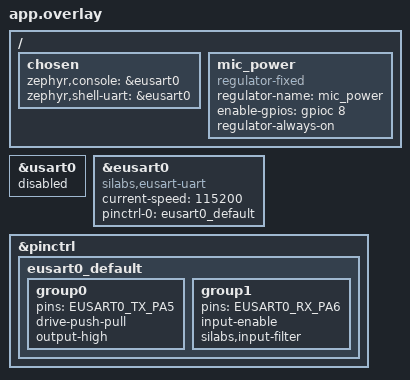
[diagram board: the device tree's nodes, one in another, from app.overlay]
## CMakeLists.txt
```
cmake_minimum_required(VERSION 3.20.0)
find_package(Zephyr REQUIRED HINTS $ENV{ZEPHYR_BASE})
project(silabs_ble_audio_peripheral)

# Module source files for audio, preprocessing, TFLM inference, and BLE
target_sources(app PRIVATE 
    src/main.cpp 
    src/audio.c 
    src/audio_preprocessing.c
    src/inference.cpp
    src/cmsis_nn_cnn_engine.cpp
    src/tcn_inference_engine.cpp
    src/ble_server.c
)

# EMLIB hardware USART and LDMA drivers
target_sources(app PRIVATE /home/acar/zephyrproject/modules/hal/silabs/gecko/emlib/src/em_usart.c)
target_sources(app PRIVATE /home/acar/zephyrproject/modules/hal/silabs/gecko/emlib/src/em_ldma.c)
```

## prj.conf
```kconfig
# =============================================================
# PROJE: Silabs BLE Audio Peripheral
# STRATEJI: USART0 tamamen Zephyr'den alinip EMLIB/I2S'e birakildi.
#           Konsol cikisi EUSART0 uzerinden PA5/PA6'ya (VCOM) yonlendirildi.
# =============================================================

# --- KONSOL: EUSART0 uzerinden UART (PA5/PA6 = VCOM) ---
CONFIG_CONSOLE=y
CONFIG_SERIAL=y
CONFIG_UART_CONSOLE=y
CONFIG_STDOUT_CONSOLE=y
CONFIG_UART_SILABS_EUSART=y

# Zephyr'in USART (eski tip) surecusunu TAMAMEN kapat
# USART0 artik sadece EMLIB tarafindan I2S icin kullanilacak
CONFIG_UART_GECKO=n

# RTT'yi de yedek olarak tut (J-Link bagliyken ise yarar)
CONFIG_USE_SEGGER_RTT=y

# --- BLUETOOTH SERVER AYARLARI (DISABLED FOR MAXIMUM 175KB TFLM ARENA) ---
CONFIG_BT=n

# --- DONANIM KONTROLU ---
CONFIG_PM=n
CONFIG_PINCTRL=y
CONFIG_GPIO=y
CONFIG_DYNAMIC_INTERRUPTS=y
CONFIG_REGULATOR=y
CONFIG_REGULATOR_FIXED=y

# Zephyr I2S/Audio/DMA suruculerini KAPATIYORUZ
# (USART0-I2S icin EMLIB + LDMA dogrudan kullaniyor)
CONFIG_I2S=n
CONFIG_AUDIO=n
CONFIG_DMA=n
CONFIG_SPI=n

# --- KORUMA VE YIGIN (OPTIMIZED STACK/HEAP) ---
CONFIG_ARM_MPU=y
CONFIG_HW_STACK_PROTECTION=y
CONFIG_MAIN_STACK_SIZE=8192
CONFIG_HEAP_MEM_POOL_SIZE=2048
CONFIG_SPEED_OPTIMIZATIONS=y

# --- GUCLENDIRILMIS GUC YONETIMI ---
CONFIG_SOC_GECKO_EMU_DCDC=y
CONFIG_SOC_GECKO_EMU_DCDC_MODE_ON=y

# --- TENSORFLOW LITE MICRO & C++ / DSP CONFIGURATION ---
CONFIG_CPP=y
CONFIG_STD_CPP17=y
CONFIG_REQUIRES_FULL_LIBCPP=y
CONFIG_CBPRINTF_FP_SUPPORT=y

# TensorFlow Lite Micro
CONFIG_TENSORFLOW_LITE_MICRO=y
CONFIG_TENSORFLOW_LITE_MICRO_CMSIS_NN_KERNELS=y
CONFIG_CMSIS_NN=y

# CMSIS-DSP Acceleration & RFFT Transformations
CONFIG_CMSIS_DSP=y
CONFIG_DSP_BACKEND_CMSIS=y
CONFIG_CMSIS_DSP_TRANSFORM=y

# Hardware Floating Point Unit (ARM Cortex-M33 FPU)
CONFIG_FPU=y
```

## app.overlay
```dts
/*
 * STRATEJI:
 * - USART0: Zephyr surucusu DEVRE DISI. EMLIB tarafindan I2S (mikrofon) icin kullanilir.
 * - EUSART0: Zephyr UART konsol surucusu AKTIF. PA5(TX)/PA6(RX) = VCOM pinleri.
 * - Mikrofon I2S pinleri (PD3/PD4/PD5) audio.c icerisinde EMLIB ile dogrudan yapilandirilir.
 */

#include <dt-bindings/pinctrl/silabs/xg24-pinctrl.h>
#include <zephyr/dt-bindings/gpio/gpio.h>
#include <silabs/xg24/clock-hfrcodpll.dtsi>

/ {
    chosen {
        /* Konsol artik EUSART0 uzerinden */
        zephyr,console = &eusart0;
        zephyr,shell-uart = &eusart0;
    };

    /* DATASHEET ONAYLI DONANIMSAL ANAHTAR (PC08/PC09) */
    mic_power: mic_power {
        compatible = "regulator-fixed";
        regulator-name = "mic_power";
        
        /* PC08 High yapilarak multiplexer aciliyor ve mikrofonlar islemciye baglaniyor */
        enable-gpios = <&gpioc 8 GPIO_ACTIVE_HIGH>;
        regulator-always-on; 
    };
};

/* USART0: Zephyr surucusunu TAMAMEN kapat. 
 * EMLIB/audio.c bunu I2S olarak dogrudan yapilandiracak. */
&usart0 {
    status = "disabled";
};

/* EUSART0: UART Konsol Surucusu (PA5=TX, PA6=RX -> VCOM) */
&eusart0 {
    compatible = "silabs,eusart-uart";
    current-speed = <115200>;
    pinctrl-0 = <&eusart0_default>;
    pinctrl-names = "default";
    status = "okay";
};

/* Pin Yapilandirmasi */
&pinctrl {
    /* EUSART0 Konsol Pinleri (VCOM'a baglanir) */
    eusart0_default: eusart0_default {
        group0 {
            pins = <EUSART0_TX_PA5>;
            drive-push-pull;
            output-high;
        };
        group1 {
            pins = <EUSART0_RX_PA6>;
            input-enable;
            silabs,input-filter;
        };
    };
};
```

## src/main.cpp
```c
#include <zephyr/kernel.h>
#include <zephyr/sys/printk.h>
#include <stdio.h>
#include <math.h>
#include "em_cmu.h"
#include "em_device.h"
#include "SEGGER_RTT.h"
#include "config.h"
#include "audio.h"
#include "audio_preprocessing.h"
#include "inference.h"
#include "ble_server.h"
#if (FIRMWARE_OPERATION_MODE == MODE_INJECT_GOLDEN_SAMPLE)
#include "golden_keyboard_typing_pcm.h"
#endif

int main(void) {
    /* 0. BOOST CPU CLOCK TO 80 MHz MAXIMUM PERFORMANCE */
    CMU_HFRCODPLLBandSet(cmuHFRCODPLLFreq_80M0Hz);
    CMU_ClockSelectSet(cmuClock_SYSCLK, cmuSelect_HFRCODPLL);
    SystemCoreClockUpdate();

    /* EARLY HEARTBEAT PRINTK (Guaranteed direct UART output to /dev/ttyACM0) */
    printk("\n\n");
    printk("************************************************************\n");
    printk(" *** EFR32MG24 BOOT TEST: UART CONSOLE LOGGING IS ALIVE! ***\n");
    printk("************************************************************\n\n");

    SEGGER_RTT_Init();
    
    uint32_t cpu_freq_hz = CMU_ClockFreqGet(cmuClock_SYSCLK);
    printf("\n============================================================\n");
    printf(" EFR32MG24 TINYML ESC-50 SOUND CLASSIFICATION PIPELINE\n");
    printf(" Target: Silicon Labs EFR32MG24 DevKit (ARM Cortex-M33)\n");
    printf(" Clock : %lu MHz High-Performance Core Clock\n", cpu_freq_hz / 1000000);
    printf(" Engine: Zephyr RTOS + TensorFlow Lite Micro (CMSIS-NN)\n");
    printf(" Mode  : %s\n", ENABLE_STREAMING_INFERENCE ? 
           "CONTINUOUS SLIDING-WINDOW STREAMING" : "ONE-SHOT CAPTURE");
    printf("============================================================\n\n");

    /* 1. Hardware & Module Initialization */
    printk("-> Step 1: Initializing hardware & TinyML modules...\n");
    audio_init();
    audio_preprocessing_init();
    
    if (inference_init() != 0) {
        printk("[FATAL] TinyML inference initialization failed!\n");
        return -1;
    }

#if ENABLE_BLE_COMMUNICATION
    ble_server_init();

    /* 2. Wait for BLE Client Connection */
    printk("\n-> Step 2: Waiting for BLE Client Connection...\n");
    while (!ble_is_connected_and_ready()) {
        printk(".");
        k_sleep(K_MSEC(500));
    }
    printk("\n-> BLE Connected!\n");
#else
    printk("\n-> [STANDALONE MODE] BLE is disabled. Starting real-time audio inference directly via UART!\n");
#endif

    void *input_tensor_ptr = inference_get_input_tensor_ptr();
    bool is_input_int8 = inference_is_input_int8();
    float scale = 1.0f;
    int32_t zero_point = 0;
    inference_get_input_quant_params(&scale, &zero_point);

#if (FIRMWARE_OPERATION_MODE == MODE_INJECT_GOLDEN_SAMPLE)
    /* ========================================================================
     * 🧪 MODE 2: DIRECT AUDIO INJECTION (GOLDEN ARRAY BENCHMARK - NO MIC)
     * ======================================================================== */
    printk("\n============================================================\n");
    printk(" 🧪 FIRMWARE MODE 2: DIRECT AUDIO INJECTION BENCHMARK\n");
    printk(" Target: Silicon Labs EFR32MG24 DevKit (ARM Cortex-M33)\n");
    printk(" Input : Golden Validation 'keyboard_typing' ESC-50 Array (5-216131-A-32.wav)\n");
    printk(" Bypassing Physical Microphone to Test DSP & Neural Network!\n");
    printk("============================================================\n\n");

    printk("-> Step 1: Running Bit-Exact On-Chip DSP Mel-Spectrogram Extraction...\n");
    audio_preprocess_run_direct(GOLDEN_KEYBOARD_TYPING_PCM, GOLDEN_AUDIO_SAMPLE_COUNT, scale, zero_point, is_input_int8, input_tensor_ptr);

    printk("-> Step 2: Executing 2-Stage Hybrid TinyML Model Inference...\n");
    int predicted_class_id = -1;
    float confidence = 0.0f;

    if (inference_run_direct(&predicted_class_id, &confidence) == 0) {
        const char *class_name = inference_get_class_name(predicted_class_id);
        printk("\n============================================================\n");
        printk(" 🏆 GOLDEN AUDIO INJECTION INFERENCE RESULT:\n");
        printk("   • Injected Sound       : 'keyboard_typing' (5-216131-A-32.wav - Official Unseen Fold-5)\n");
        printk("   • Predicted Class ID   : %d\n", predicted_class_id);
        printk("   • Predicted Sound Name : '%s'\n", class_name);
        printk("   • Prediction Confidence: %d%%\n", (int)(confidence * 100.0f));
        printk("============================================================\n\n");
    } else {
        printk("[ERROR] Inference execution failed!\n");
    }

    while (1) {
        k_sleep(K_SECONDS(2));
    }

#elif (FIRMWARE_OPERATION_MODE == MODE_AUDIO_DUMP_TO_PC)
    /* ========================================================================
     * 🎙️ DIAGNOSTIC MODE: STREAM 3-SECOND MICROPHONE AUDIO TO PC (WAV DUMP)
     * ======================================================================== */
    printk("\n============================================================\n");
    printk(" 🎙️ FIRMWARE MODE: 3-SECOND MICROPHONE AUDIO DUMP TO PC\n");
    printk(" Target: Silicon Labs EFR32MG24 DevKit\n");
    printk(" Rate  : 16000 Hz, 16-bit PCM Mono, Total: 48000 samples (3 sec)\n");
    printk(" Speak, type, or play sounds near the board now!\n");
    printk("============================================================\n\n");

    int dump_iteration = 0;
    while (1) {
        printk("\n-> [READY #%d] 🎙️ Recording 3 seconds of live audio from mic...\n", ++dump_iteration);
        printk("=== AUDIO_DUMP_START ===\n");

        for (int sec = 0; sec < DUMP_RECORD_SECONDS; sec++) {
            audio_record_to_ram();
            int16_t *raw_pcm = get_audio_buffer();

            for (int i = 0; i < AUDIO_RING_BUFFER_SAMPLES; i++) {
                printk("%d\n", (int)raw_pcm[i]);
            }
        }

        printk("=== AUDIO_DUMP_END ===\n");
        printk("-> [OK] 3-second capture complete! Waiting 3 seconds before next clip...\n");
        k_sleep(K_SECONDS(3));
    }

#elif (FIRMWARE_OPERATION_MODE == MODE_REALTIME_INFERENCE)
    /* ========================================================================
     * 🧠 MODE 0: CONTINUOUS SLIDING-WINDOW STREAMING INFERENCE
     * ======================================================================== */
    printk("\n-> [CONTINUOUS STREAMING MODE] Starting Real-Time Acoustic Inference Loop...\n");
    
    /* Zero-initialize the TFLM input tensor buffer to true silence (-128) */
    if (is_input_int8) {
        memset(input_tensor_ptr, -128, SPECTROGRAM_TOTAL_ELEMENTS);
    } else {
        memset(input_tensor_ptr, 0, sizeof(float) * SPECTROGRAM_TOTAL_ELEMENTS);
    }

    /* Squelch threshold defined in config.h (SILENCE_AC_RMS_THRESHOLD) */
    const float SOUND_CONFIDENCE_THRESHOLD = 0.20f; /* 20% minimum confidence (10x random chance in 50 classes) */
    int inference_counter = 0;

    while (1) {
        /* 1. Record 1.0-second audio chunk directly into audio_ring_buffer */
        audio_record_to_ram();
        int16_t *raw_pcm = get_audio_buffer();

        /* 2. Calculate DC Mean & True AC RMS */
        int64_t sum_samples = 0;
        for (int i = 0; i < AUDIO_RING_BUFFER_SAMPLES; i++) {
            sum_samples += raw_pcm[i];
        }
        int16_t dc_mean = (int16_t)(sum_samples / AUDIO_RING_BUFFER_SAMPLES);

        int64_t sum_ac_sq = 0;
        for (int i = 0; i < AUDIO_RING_BUFFER_SAMPLES; i++) {
            int16_t ac_s = raw_pcm[i] - dc_mean;
            sum_ac_sq += ((int32_t)ac_s * ac_s);
        }
        int ac_rms = (int)sqrtf((float)(sum_ac_sq / AUDIO_RING_BUFFER_SAMPLES));

        /* 3. Compute and tile active Mel chunk across full 5.0s (313 frames) to eliminate temporal dilution */
        uint32_t t_dsp_start = k_cycle_get_32();
        audio_preprocess_tile_chunk_direct(raw_pcm, AUDIO_RING_BUFFER_SAMPLES, scale, zero_point, is_input_int8, input_tensor_ptr);
        uint32_t t_dsp_end = k_cycle_get_32();
        uint32_t dsp_time_us = k_cyc_to_us_near32(t_dsp_end - t_dsp_start);

        /* 4. Evaluate Dual-Stage Silence & Confidence Thresholds */
        uint32_t uptime_ms = k_uptime_get_32();
        if (ac_rms < SILENCE_AC_RMS_THRESHOLD) {
            printk("[%02d:%02d.%03d] [#%04d] 🎙️ [AC-RMS: %4d | DSP: %.2f ms] -> [Quiet / Ambient Silence]\n", 
                   (uptime_ms / 60000) % 60, (uptime_ms / 1000) % 60, uptime_ms % 1000,
                   ++inference_counter, ac_rms, (float)dsp_time_us / 1000.0f);
        } else {
            /* Run Hybrid 2-Stage Model Inference */
            int predicted_class_id = -1;
            float confidence = 0.0f;

            if (inference_run_direct(&predicted_class_id, &confidence) == 0) {
                if (confidence >= SOUND_CONFIDENCE_THRESHOLD) {
                    const char *class_name = inference_get_class_name(predicted_class_id);
                    printk("[%02d:%02d.%03d] [#%04d] 🎙️ [AC-RMS: %5d | DSP: %.2f ms] -> 🎯 CONFIDENT SOUND: %-20s (Conf: %2d%%) 🌟\n",
                           (uptime_ms / 60000) % 60, (uptime_ms / 1000) % 60, uptime_ms % 1000,
                           ++inference_counter, ac_rms, (float)dsp_time_us / 1000.0f, class_name, (int)(confidence * 100.0f));
                }
            }
        }
    }
#endif

    return 0;
}
```

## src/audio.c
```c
#include "audio.h"
#include "em_ldma.h"
#include "em_device.h"
#include "em_cmu.h"
#include "em_usart.h"
#include "em_gpio.h" 
#include <zephyr/kernel.h>
#include <zephyr/irq.h>
#include <stdio.h>
#include <stdlib.h>
#include <string.h>

#define DMA_BUF_WORDS 1024

/* ============================================================================
 * AUDIO RING BUFFER CONFIGURATION
 * To eliminate linker RAM overflow and save >125 KB of microcontroller SRAM,
 * we maintain a 1-second streaming ring buffer (16,000 samples = 32 KB RAM)
 * instead of a monolithic 5-second 160 KB array.
 * ============================================================================ */
#ifndef AUDIO_RING_BUFFER_SAMPLES
#define AUDIO_RING_BUFFER_SAMPLES (SAMPLE_RATE * 1) /* 16,000 samples = 32 KB RAM */
#endif

static int16_t audio_ring_buffer[AUDIO_RING_BUFFER_SAMPLES];
static uint16_t dma_buf[DMA_BUF_WORDS] __attribute__((aligned(4)));
static LDMA_Descriptor_t dma_desc;

static void check_usart_errors(const char* stage) {
    uint32_t if_flags = USART0->IF;
    uint32_t status = USART0->STATUS;
    
    printf("\n--- [USART DONANIM HATA VE DURUM ANALIZI: %s] ---\n", stage);
    printf("  USART0->IF     = 0x%08X\n", if_flags);
    printf("  USART0->STATUS = 0x%08X\n", status);
    
    bool err = false;
    if (if_flags & (1 << 4))  { printf("  [!] RXOF : Alici FIFO Tasmasi (RX Overflow)!\n"); err = true; }
    if (if_flags & (1 << 5))  { printf("  [!] RXUF : Alici FIFO Bos Okuma (RX Underflow)!\n"); err = true; }
    if (if_flags & (1 << 6))  { printf("  [!] TXOF : Verici FIFO Tasmasi (TX Overflow)!\n"); err = true; }
    if (if_flags & (1 << 7))  { printf("  [!] TXUF : Verici Underflow (TX Underflow)!\n"); err = true; }
    if (if_flags & (1 << 8))  { printf("  [!] PERR : Parite Hatasi!\n"); err = true; }
    if (if_flags & (1 << 9))  { printf("  [!] FERR : Cerceveleme Hatasi!\n"); err = true; }
    if (if_flags & (1 << 12)) { printf("  [!] CCF  : Cakisma Hatasi!\n"); err = true; }
    
    if (!err) {
        printf("  [OK] Hicbir donanim hata bayragi aktif degil.\n");
    }
    
    printf("  Anlik Durum: RX_Aktif=%d, TX_Aktif=%d, RXDATAV=%d, RXFULL=%d\n",
           (status & (1 << 1)) ? 1 : 0,
           (status & (1 << 0)) ? 1 : 0,
           (status & (1 << 7)) ? 1 : 0,
           (status & (1 << 8)) ? 1 : 0);
    printf("-------------------------------------------------------------\n");
}

void audio_init(void) {
    printf("-> Donanim seviyesinde I2S ve Guc baslatiliyor...\n");

    /* 1. Saatleri Ac */
    CMU_ClockEnable(cmuClock_USART0, true);
    CMU_ClockEnable(cmuClock_GPIO, true); 

    /* 2. MIKROFON GUCU (PC08 ve PC09) */
    GPIO_PinModeSet(gpioPortC, 8, gpioModePushPull, 1);
    GPIO_PinModeSet(gpioPortC, 9, gpioModePushPull, 1);

    k_sleep(K_MSEC(50)); 

    /* FIZIKSEL PINLERI DIS DUNYAYA AC */
    GPIO_PinModeSet(gpioPortD, 3, gpioModePushPull, 0); /* CLK */
    GPIO_PinModeSet(gpioPortD, 5, gpioModePushPull, 0); /* WS */
    GPIO_PinModeSet(gpioPortD, 4, gpioModeInput, 0);    /* RX */

    GPIO->USARTROUTE[0].CLKROUTE = (gpioPortD << _GPIO_USART_CLKROUTE_PORT_SHIFT) | (3 << _GPIO_USART_CLKROUTE_PIN_SHIFT);
    GPIO->USARTROUTE[0].RXROUTE  = (gpioPortD << _GPIO_USART_RXROUTE_PORT_SHIFT)  | (4 << _GPIO_USART_RXROUTE_PIN_SHIFT);
    GPIO->USARTROUTE[0].CSROUTE  = (gpioPortD << _GPIO_USART_CSROUTE_PORT_SHIFT)  | (5 << _GPIO_USART_CSROUTE_PIN_SHIFT);

    /* DONANIM MATRISI (ROUTE) */
    GPIO->USARTROUTE[0].ROUTEEN = GPIO_USART_ROUTEEN_CLKPEN | 
                                  GPIO_USART_ROUTEEN_RXPEN  | 
                                  GPIO_USART_ROUTEEN_CSPEN;

    /* I2S YAPILANDIRMASI: W32D16 Stereo */
    USART_InitI2s_TypeDef init = USART_INITI2S_DEFAULT;
    init.sync.baudrate = 1024000;
    init.sync.enable = usartEnable; 
    init.sync.master = true;
    init.format = usartI2sFormatW32D16;
    init.mono = false;
    init.sync.autoTx = true;
    init.sync.autoCsEnable = true;
    USART_InitI2s(USART0, &init);

    /* Databits 16 zorla */
    USART0->FRAME = (USART0->FRAME & ~_USART_FRAME_DATABITS_MASK) | USART_FRAME_DATABITS_SIXTEEN;

    USART_Tx(USART0, 0x00000000);

    /* SAATI ATES (AUTOTX) */
    USART0->CTRL |= USART_CTRL_AUTOTX;
    USART_Enable(USART0, usartEnable); 
    USART0->TXDATA = 0x0000; 

    printf("-> [OK] I2S Hazir! W32D16 Stereo modu aktif.\n");
    
    /* LDMA HAZIRLIGI */
    CMU_ClockEnable(cmuClock_LDMA, true);
    LDMA_Init_t ldma_init = LDMA_INIT_DEFAULT;
    LDMA_Init(&ldma_init);
    NVIC_DisableIRQ(LDMA_IRQn);
}

static int internal_record_to_buffer(int16_t *buffer, int num_samples) {
    memset(dma_buf, 0, sizeof(dma_buf));
    USART0->IF_CLR = 0xFFFFFFFF; 
    
    k_sleep(K_MSEC(10));

    USART0->CMD = USART_CMD_CLEARRX;
    
    LDMA_TransferCfg_t transfer_cfg = LDMA_TRANSFER_CFG_PERIPHERAL(ldmaPeripheralSignal_USART0_RXDATAV);

    dma_desc = (LDMA_Descriptor_t)LDMA_DESCRIPTOR_LINKREL_P2M_WORD(
        (void*)&(USART0->RXDOUBLE), 
        dma_buf,                  
        DMA_BUF_WORDS,
        0
    );
    dma_desc.xfer.size = ldmaCtrlSizeHalf;     /* 16-BIT TRANSFER */
    dma_desc.xfer.dstInc = ldmaCtrlSrcIncOne;  

    /* Tam Sol kanalin (WS=0) basladigi ANI yakala */
    while (GPIO_PinInGet(gpioPortD, 5) == 0);
    while (GPIO_PinInGet(gpioPortD, 5) == 1);

    USART0->CMD = USART_CMD_CLEARRX;
    LDMA_StartTransfer(0, &transfer_cfg, &dma_desc);
    
    int read_idx = 0;
    int interrupt_key = irq_lock();
    int catchup_count = 0;

    for (int i = 0; i < num_samples; ) {
        uint32_t current_dst = LDMA->CH[0].DST;
        int write_idx = ((current_dst - (uint32_t)dma_buf) / 2) & (DMA_BUF_WORDS - 1);
        int available = (write_idx - read_idx + DMA_BUF_WORDS) & (DMA_BUF_WORDS - 1);

        if (available > DMA_BUF_WORDS - 8) {
            catchup_count++;
            read_idx = (write_idx - 8 + DMA_BUF_WORDS) & (DMA_BUF_WORDS - 1);
            read_idx &= ~1; 
            available = 8;
        }

        if (available >= 2) {
            int16_t raw_l = (int16_t)dma_buf[read_idx];
            int16_t raw_r = (int16_t)dma_buf[read_idx + 1];
            read_idx = (read_idx + 2) & (DMA_BUF_WORDS - 1);
            
            /* Automatically select active microphone channel (Left vs Right) */
            int16_t raw_sample = (abs((int)raw_l) >= abs((int)raw_r)) ? raw_l : raw_r;
            
            /* Software Digital Gain with Saturation Protection */
            int32_t amplified = (int32_t)raw_sample * AUDIO_SOFTWARE_GAIN_MULTIPLIER;
            if (amplified > 32767) amplified = 32767;
            if (amplified < -32768) amplified = -32768;
            buffer[i] = (int16_t)amplified;
            i++;
        } else {
            irq_unlock(interrupt_key);
            k_busy_wait(20); 
            interrupt_key = irq_lock();
        }
    }

    irq_unlock(interrupt_key);
    LDMA_StopTransfer(0);
    return num_samples;
}

int audio_record_to_ram(void) {
    memset(audio_ring_buffer, 0, sizeof(audio_ring_buffer));
    return internal_record_to_buffer(audio_ring_buffer, AUDIO_RING_BUFFER_SAMPLES);
}

int audio_record_chunk(int16_t *out_chunk, int num_samples) {
    return internal_record_to_buffer(out_chunk, num_samples);
}

void audio_update_ring_buffer(const int16_t *new_chunk, int num_samples) {
    if (num_samples >= AUDIO_RING_BUFFER_SAMPLES) {
        memcpy(audio_ring_buffer, new_chunk + (num_samples - AUDIO_RING_BUFFER_SAMPLES), sizeof(int16_t) * AUDIO_RING_BUFFER_SAMPLES);
        return;
    }
    
    int keep_samples = AUDIO_RING_BUFFER_SAMPLES - num_samples;
    /* Shift old audio left */
    memmove(audio_ring_buffer, audio_ring_buffer + num_samples, sizeof(int16_t) * keep_samples);
    /* Append new audio chunk at tail */
    memcpy(audio_ring_buffer + keep_samples, new_chunk, sizeof(int16_t) * num_samples);
}

int16_t* get_audio_buffer(void) {
    return audio_ring_buffer;
}
```

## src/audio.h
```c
#ifndef AUDIO_H
#define AUDIO_H

#include <stdint.h>
#include "config.h"

#ifdef __cplusplus
extern "C" {
#endif

/**
 * @brief Initializes I2S hardware, clocks, DMA (LDMA), and microphone power pins.
 */
void audio_init(void);

/**
 * @brief Records raw full PCM audio samples (TOTAL_SAMPLES) from hardware microphone into RAM.
 * @return Number of captured 16-bit PCM audio samples.
 */
int audio_record_to_ram(void);

/**
 * @brief Records a continuous chunk of PCM audio samples (e.g. 1 second stride) from hardware I2S.
 * @param out_chunk Buffer to receive new PCM samples.
 * @param num_samples Number of samples to capture.
 * @return Number of captured samples.
 */
int audio_record_chunk(int16_t *out_chunk, int num_samples);

/**
 * @brief Shifts the 5-second trailing audio buffer left and appends new incoming samples.
 * @param new_chunk Pointer to new audio samples.
 * @param num_samples Number of new audio samples.
 */
void audio_update_ring_buffer(const int16_t *new_chunk, int num_samples);

/**
 * @brief Gets pointer to the current trailing 5-second PCM audio buffer.
 * @return Pointer to raw audio sample buffer (80,000 samples).
 */
int16_t* get_audio_buffer(void);

#ifdef __cplusplus
}
#endif

#endif /* AUDIO_H */
```

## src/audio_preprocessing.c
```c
#include "audio_preprocessing.h"
#include "mel_filterbank_tables.h"
#include "config.h"
#include <stdio.h>
#include <math.h>
#include <string.h>

#if defined(CONFIG_CMSIS_DSP)
#include <arm_math.h>
#endif

static bool is_preproc_initialized = false;

#if defined(CONFIG_CMSIS_DSP)
static arm_rfft_fast_instance_f32 rfft_instance;
#endif

static float fft_buf[FFT_SIZE];
static float fft_output[FFT_SIZE];
static float power_spectrum[NUM_FREQ_BINS];

void audio_preprocessing_init(void) {
    if (is_preproc_initialized) return;

#if defined(CONFIG_CMSIS_DSP)
    arm_rfft_fast_init_f32(&rfft_instance, FFT_SIZE);
#endif

    is_preproc_initialized = true;
    printf("-> [OK] Audio preprocessing DSP module initialized (Bit-Exact Torchaudio Mel Filterbank - 0 Extra RAM).\n");
}

int32_t audio_preprocess_compute_dc(const int16_t *raw_pcm, int num_samples) {
    int64_t sum = 0;
    for (int i = 0; i < num_samples; i++) {
        sum += raw_pcm[i];
    }
    return (int32_t)(sum / num_samples);
}

static void compute_frame_power_spectrum_onthefly(
    const int16_t *raw_pcm, 
    int frame_idx, 
    int num_samples, 
    int32_t dc_offset) 
{
    for (int n = 0; n < FFT_SIZE; n++) {
        int audio_idx = frame_idx * HOP_LENGTH - (FFT_SIZE / 2) + n;
        if (audio_idx < 0) {
            audio_idx = -audio_idx; /* Reflect padding left */
        } else if (audio_idx >= num_samples) {
            audio_idx = 2 * (num_samples - 1) - audio_idx; /* Reflect padding right */
            if (audio_idx < 0) audio_idx = 0;
        }

        float raw_curr = (float)(raw_pcm[audio_idx] - dc_offset) / 32768.0f;
        /* Standard Bit-Exact Torchaudio Windowing (No pre-emphasis distortion) */
        float sample_val = raw_curr;
        fft_buf[n] = sample_val * HANN_WINDOW_512[n];
    }

#if defined(CONFIG_CMSIS_DSP)
    arm_rfft_fast_f32(&rfft_instance, fft_buf, fft_output, 0);

    power_spectrum[0] = fft_output[0] * fft_output[0];
    power_spectrum[NUM_FREQ_BINS - 1] = fft_output[1] * fft_output[1];

    for (int k = 1; k < NUM_FREQ_BINS - 1; k++) {
        float real = fft_output[2 * k];
        float imag = fft_output[2 * k + 1];
        power_spectrum[k] = real * real + imag * imag;
    }
#else
    for (int k = 0; k < NUM_FREQ_BINS; k++) {
        float real = 0.0f;
        float imag = 0.0f;
        for (int n = 0; n < FFT_SIZE; n++) {
            float angle = (2.0f * 3.14159265358979323846f * k * n) / FFT_SIZE;
            real += fft_buf[n] * cosf(angle);
            imag -= fft_buf[n] * sinf(angle);
        }
        power_spectrum[k] = real * real + imag * imag;
    }
#endif
}

void audio_preprocess_extract_melspectrogram_direct(
    const int16_t *raw_pcm, 
    int num_samples, 
    int32_t dc_offset, 
    float scale, 
    int32_t zero_point, 
    bool is_int8, 
    void *out_tensor_ptr) 
{
    if (!is_preproc_initialized) {
        audio_preprocessing_init();
    }

    if (scale == 0.0f) scale = 1.0f;
    int8_t *int8_buf = (int8_t*)out_tensor_ptr;
    float *float_buf = (float*)out_tensor_ptr;

    for (int t = 0; t < SPECTROGRAM_TIME_STEPS; t++) {
        /* 1. On-the-fly Power Spectrum with Exact Reflect Padding (313 Frames) */
        compute_frame_power_spectrum_onthefly(raw_pcm, t, num_samples, dc_offset);

        /* 2. Exact Sparse Mel Matrix Multiplication + Direct Input Tensor Writing */
        for (int m = 0; m < N_MELS; m++) {
            float mel_energy = 0.0f;
            uint16_t start_k = MEL_FILTERS[m].start_bin;
            uint16_t count_k = MEL_FILTERS[m].num_bins;
            const float *w_ptr = MEL_FILTERS[m].weights;

            for (uint16_t k = 0; k < count_k; k++) {
                mel_energy += power_spectrum[start_k + k] * w_ptr[k];
            }

            float log_mel = logf(mel_energy + 1e-6f);
            int spec_index = m * SPECTROGRAM_TIME_STEPS + t;

            if (is_int8) {
                int32_t quantized = (int32_t)lroundf(log_mel / scale) + zero_point;
                if (quantized < -128) quantized = -128;
                if (quantized > 127)  quantized = 127;
                int8_buf[spec_index] = (int8_t)quantized;
            } else {
                float_buf[spec_index] = log_mel;
            }
        }
    }

    if (is_int8) {
        printf("-> [DSP] Spectrogram Extracted: Mel 0, Time 0..4 INT8: %d, %d, %d, %d, %d\n",
               int8_buf[0], int8_buf[1], int8_buf[2], int8_buf[3], int8_buf[4]);
    }
}

void audio_preprocess_run_direct(
    const int16_t *raw_pcm, 
    int num_samples, 
    float scale, 
    int32_t zero_point, 
    bool is_int8, 
    void *out_tensor_ptr) 
{
    int32_t dc_offset = 0; /* Exact floating-point parity for normalized audio */
    audio_preprocess_extract_melspectrogram_direct(
        raw_pcm, num_samples, dc_offset, scale, zero_point, is_int8, out_tensor_ptr
    );
}

void audio_preprocess_append_chunk_direct(
    const int16_t *new_pcm_chunk, 
    int num_samples, 
    float scale, 
    int32_t zero_point, 
    bool is_int8, 
    void *out_tensor_ptr)
{
    if (!is_preproc_initialized) {
        audio_preprocessing_init();
    }
    if (scale == 0.0f) scale = 1.0f;
    int8_t *int8_buf = (int8_t*)out_tensor_ptr;
    float *float_buf = (float*)out_tensor_ptr;

    int new_frames = 0;
    if (num_samples >= FFT_SIZE) {
        new_frames = (num_samples - FFT_SIZE) / HOP_LENGTH + 1;
    }
    if (num_samples >= 79000 || new_frames > SPECTROGRAM_TIME_STEPS) {
        new_frames = SPECTROGRAM_TIME_STEPS;
    }
    if (new_frames <= 0) return;

    int keep_frames = SPECTROGRAM_TIME_STEPS - new_frames;

    /* 1. Shift existing spectrogram frames left by new_frames in-place */
    for (int m = 0; m < N_MELS; m++) {
        if (is_int8) {
            memmove(int8_buf + (m * SPECTROGRAM_TIME_STEPS), 
                    int8_buf + (m * SPECTROGRAM_TIME_STEPS) + new_frames, 
                    keep_frames);
        } else {
            memmove(float_buf + (m * SPECTROGRAM_TIME_STEPS), 
                    float_buf + (m * SPECTROGRAM_TIME_STEPS) + new_frames, 
                    sizeof(float) * keep_frames);
        }
    }

    int32_t dc_offset = audio_preprocess_compute_dc(new_pcm_chunk, num_samples);
    float power_spectrum[NUM_FREQ_BINS];

    /* 2. Calculate new Mel frames and append to tail */
    for (int t = 0; t < new_frames; t++) {
        int sample_offset = (num_samples >= 79000) ? ((t - 1) * HOP_LENGTH) : (t * HOP_LENGTH);
        
        float fft_buf[FFT_SIZE];
        float fft_output[FFT_SIZE];

        for (int n = 0; n < FFT_SIZE; n++) {
            float sample_val = 0.0f;
            int sample_idx = sample_offset + n;
            if (sample_idx >= 0 && sample_idx < num_samples) {
                sample_val = (float)(new_pcm_chunk[sample_idx] - dc_offset) / 32768.0f;
            }
            fft_buf[n] = sample_val * HANN_WINDOW_512[n];
        }

#if defined(CONFIG_CMSIS_DSP)
        arm_rfft_fast_f32(&rfft_instance, fft_buf, fft_output, 0);

        power_spectrum[0] = fft_output[0] * fft_output[0];
        power_spectrum[NUM_FREQ_BINS - 1] = fft_output[1] * fft_output[1];

        for (int k = 1; k < NUM_FREQ_BINS - 1; k++) {
            float real = fft_output[2 * k];
            float imag = fft_output[2 * k + 1];
            power_spectrum[k] = real * real + imag * imag;
        }
#else
        for (int k = 0; k < NUM_FREQ_BINS; k++) {
            float real = 0.0f;
            float imag = 0.0f;
            for (int n = 0; n < FFT_SIZE; n++) {
                float angle = (2.0f * 3.14159265358979323846f * k * n) / FFT_SIZE;
                real += fft_buf[n] * cosf(angle);
                imag -= fft_buf[n] * sinf(angle);
            }
            power_spectrum[k] = real * real + imag * imag;
        }
#endif

        int time_index = keep_frames + t;

        for (int m = 0; m < N_MELS; m++) {
            float mel_energy = 0.0f;
            uint16_t start_k = MEL_FILTERS[m].start_bin;
            uint16_t count_k = MEL_FILTERS[m].num_bins;
            const float *w_ptr = MEL_FILTERS[m].weights;

            for (uint16_t k = 0; k < count_k; k++) {
                mel_energy += power_spectrum[start_k + k] * w_ptr[k];
            }

            float log_mel = logf(mel_energy + 1e-6f);
            int spec_index = m * SPECTROGRAM_TIME_STEPS + time_index;

            if (is_int8) {
                int32_t quantized = (int32_t)lroundf(log_mel / scale) + zero_point;
                if (quantized < -128) quantized = -128;
                if (quantized > 127)  quantized = 127;
                int8_buf[spec_index] = (int8_t)quantized;
            } else {
                float_buf[spec_index] = log_mel;
            }
        }
    }
}

void audio_preprocess_tile_chunk_direct(
    const int16_t *new_pcm_chunk, 
    int num_samples, 
    float scale, 
    int32_t zero_point, 
    bool is_int8, 
    void *out_tensor_ptr) 
{
    if (out_tensor_ptr == NULL || new_pcm_chunk == NULL) return;
    if (scale == 0.0f) scale = 1.0f;
    int8_t *int8_buf = (int8_t*)out_tensor_ptr;
    float *float_buf = (float*)out_tensor_ptr;

    int new_frames = 0;
    if (num_samples >= FFT_SIZE) {
        new_frames = (num_samples - FFT_SIZE) / HOP_LENGTH + 1;
    }
    if (new_frames > SPECTROGRAM_TIME_STEPS) {
        new_frames = SPECTROGRAM_TIME_STEPS;
    }
    if (new_frames <= 0) return;

    int32_t dc_offset = audio_preprocess_compute_dc(new_pcm_chunk, num_samples);
    float power_spectrum[NUM_FREQ_BINS];

    /* 1. Calculate Mel frames for the newly captured audio chunk into the first new_frames slots */
    for (int t = 0; t < new_frames; t++) {
        int sample_offset = t * HOP_LENGTH;
        float fft_buf[FFT_SIZE];
        float fft_output[FFT_SIZE];

        for (int n = 0; n < FFT_SIZE; n++) {
            float sample_val = 0.0f;
            int sample_idx = sample_offset + n;
            if (sample_idx >= 0 && sample_idx < num_samples) {
                float raw_curr = (float)(new_pcm_chunk[sample_idx] - dc_offset) / 32768.0f;
                sample_val = raw_curr;
            }
            fft_buf[n] = sample_val * HANN_WINDOW_512[n];
        }

#if defined(CONFIG_CMSIS_DSP)
        arm_rfft_fast_f32(&rfft_instance, fft_buf, fft_output, 0);

        power_spectrum[0] = fft_output[0] * fft_output[0];
        power_spectrum[NUM_FREQ_BINS - 1] = fft_output[1] * fft_output[1];

        for (int k = 1; k < NUM_FREQ_BINS - 1; k++) {
            float real = fft_output[2 * k];
            float imag = fft_output[2 * k + 1];
            power_spectrum[k] = real * real + imag * imag;
        }
#else
        for (int k = 0; k < NUM_FREQ_BINS; k++) {
            float real = 0.0f;
            float imag = 0.0f;
            for (int n = 0; n < FFT_SIZE; n++) {
                float angle = (2.0f * 3.14159265358979323846f * k * n) / FFT_SIZE;
                real += fft_buf[n] * cosf(angle);
                imag -= fft_buf[n] * sinf(angle);
            }
            power_spectrum[k] = real * real + imag * imag;
        }
#endif

        for (int m = 0; m < N_MELS; m++) {
            float mel_energy = 0.0f;
            uint16_t start_k = MEL_FILTERS[m].start_bin;
            uint16_t count_k = MEL_FILTERS[m].num_bins;
            const float *w_ptr = MEL_FILTERS[m].weights;

            for (uint16_t k = 0; k < count_k; k++) {
                mel_energy += power_spectrum[start_k + k] * w_ptr[k];
            }

            float log_mel = logf(mel_energy + 1e-6f);
            int spec_index = m * SPECTROGRAM_TIME_STEPS + t;

            if (is_int8) {
                int32_t quantized = (int32_t)lroundf(log_mel / scale) + zero_point;
                if (quantized < -128) quantized = -128;
                if (quantized > 127)  quantized = 127;
                int8_buf[spec_index] = (int8_t)quantized;
            } else {
                float_buf[spec_index] = log_mel;
            }
        }
    }

    /* 2. Seamlessly tile the active chunk across all 313 frames of the 5.0-second tensor */
    for (int m = 0; m < N_MELS; m++) {
        for (int t = new_frames; t < SPECTROGRAM_TIME_STEPS; t++) {
            int src_t = t % new_frames;
            int dst_idx = m * SPECTROGRAM_TIME_STEPS + t;
            int src_idx = m * SPECTROGRAM_TIME_STEPS + src_t;

            if (is_int8) {
                int8_buf[dst_idx] = int8_buf[src_idx];
            } else {
                float_buf[dst_idx] = float_buf[src_idx];
            }
        }
    }
}

void audio_preprocess_quantize_int8(const float *in_spectrogram, int8_t *out_int8_tensor, float scale, int32_t zero_point) {
    if (scale == 0.0f) scale = 1.0f;

    for (int i = 0; i < SPECTROGRAM_TOTAL_ELEMENTS; i++) {
        float val = in_spectrogram[i];
        int32_t quantized = (int32_t)lroundf(val / scale) + zero_point;
        
        if (quantized < -128) quantized = -128;
        if (quantized > 127)  quantized = 127;
        
        out_int8_tensor[i] = (int8_t)quantized;
    }
}
```

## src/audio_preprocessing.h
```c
#ifndef AUDIO_PREPROCESSING_H
#define AUDIO_PREPROCESSING_H

#include <stdint.h>
#include <stdbool.h>
#include "config.h"

#ifdef __cplusplus
extern "C" {
#endif

/**
 * @brief Initializes audio preprocessing module (Mel filterbank weights, window functions).
 */
void audio_preprocessing_init(void);

/**
 * @brief Computes DC offset average from raw 16-bit PCM audio samples.
 * @param raw_pcm Pointer to raw int16 PCM audio samples.
 * @param num_samples Number of samples in raw_pcm.
 * @return Calculated DC offset value.
 */
int32_t audio_preprocess_compute_dc(const int16_t *raw_pcm, int num_samples);

/**
 * @brief Performs Log-Mel extraction and direct quantization into the model input tensor (0 extra RAM).
 * @param raw_pcm Pointer to raw int16 PCM audio samples.
 * @param num_samples Number of samples.
 * @param dc_offset Pre-computed DC offset.
 * @param scale TFLM input tensor scale factor.
 * @param zero_point TFLM input tensor zero point.
 * @param is_int8 True if model input is INT8, false if FP32.
 * @param out_tensor_ptr Pointer directly to TFLM input tensor buffer.
 */
void audio_preprocess_extract_melspectrogram_direct(
    const int16_t *raw_pcm, 
    int num_samples, 
    int32_t dc_offset, 
    float scale, 
    int32_t zero_point, 
    bool is_int8, 
    void *out_tensor_ptr
);

/**
 * @brief Full end-to-end preprocessing pipeline directly writing to TFLM input tensor (0 extra RAM).
 * @param raw_pcm Pointer to raw int16 PCM audio buffer.
 * @param num_samples Number of samples in raw_pcm.
 * @param scale TFLM input tensor scale factor.
 * @param zero_point TFLM input tensor zero point.
 * @param is_int8 True if model input is INT8, false if FP32.
 * @param out_tensor_ptr Pointer directly to TFLM input tensor buffer.
 */
void audio_preprocess_run_direct(
    const int16_t *raw_pcm, 
    int num_samples, 
    float scale, 
    int32_t zero_point, 
    bool is_int8, 
    void *out_tensor_ptr
);

/**
 * @brief Shifts existing spectrogram frames in TFLM input tensor left and appends newly computed Mel frames (0 extra RAM).
 */
void audio_preprocess_append_chunk_direct(
    const int16_t *new_pcm_chunk, 
    int num_samples, 
    float scale, 
    int32_t zero_point, 
    bool is_int8, 
    void *out_tensor_ptr
);

/**
 * @brief Computes Mel frames for an active audio chunk and tiles it across the full 5.0s (313 frames) TFLM input tensor.
 * Eliminates temporal dilution during real-time streaming (0 extra RAM).
 */
void audio_preprocess_tile_chunk_direct(
    const int16_t *new_pcm_chunk, 
    int num_samples, 
    float scale, 
    int32_t zero_point, 
    bool is_int8, 
    void *out_tensor_ptr
);

/**
 * @brief Quantizes floating-point Log-Mel Spectrogram features into model INT8 tensor format.
 */
void audio_preprocess_quantize_int8(const float *in_spectrogram, int8_t *out_int8_tensor, float scale, int32_t zero_point);

#ifdef __cplusplus
}
#endif

#endif /* AUDIO_PREPROCESSING_H */
```

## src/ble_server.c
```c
#include "ble_server.h"
#include <zephyr/kernel.h>
#include <stdio.h>

#if defined(CONFIG_BT) && (CONFIG_BT == 1)
#include <zephyr/bluetooth/bluetooth.h>
#include <zephyr/bluetooth/hci.h>
#include <zephyr/bluetooth/uuid.h>
#include <zephyr/bluetooth/gatt.h>

#define CUSTOM_SERVICE_UUID \
    BT_UUID_DECLARE_128(BT_UUID_128_ENCODE(0x12345678, 0x1234, 0x5678, 0x1234, 0x56789abcdef0))

#define CUSTOM_CHAR_UUID \
    BT_UUID_DECLARE_128(BT_UUID_128_ENCODE(0x12345678, 0x1234, 0x5678, 0x1234, 0x56789abcdef1))

static bool is_connected = false;
static bool notify_enabled = false;
static struct bt_conn *active_conn = NULL;

static void ccc_cfg_changed(const struct bt_gatt_attr *attr, uint16_t value) {
    notify_enabled = (value == BT_GATT_CCC_NOTIFY);
    printf("[BLE] Karsi cihazdan Bildirim (Notify) %s!\n", notify_enabled ? "ACILDI" : "KAPATILDI");
}

BT_GATT_SERVICE_DEFINE(my_custom_svc,
    BT_GATT_PRIMARY_SERVICE(CUSTOM_SERVICE_UUID),
    BT_GATT_CHARACTERISTIC(CUSTOM_CHAR_UUID, BT_GATT_CHRC_NOTIFY, BT_GATT_PERM_NONE, NULL, NULL, NULL),
    BT_GATT_CCC(ccc_cfg_changed, BT_GATT_PERM_READ | BT_GATT_PERM_WRITE)
);

static const struct bt_data ad[] = {
    BT_DATA_BYTES(BT_DATA_FLAGS, (BT_LE_AD_GENERAL | BT_LE_AD_NO_BREDR)),
};

static const struct bt_data sd[] = {
    BT_DATA(BT_DATA_NAME_COMPLETE, CONFIG_BT_DEVICE_NAME, sizeof(CONFIG_BT_DEVICE_NAME) - 1),
};

static void connected(struct bt_conn *conn, uint8_t err) {
    if (!err) {
        is_connected = true;
        active_conn = bt_conn_ref(conn);
        printf("\n[BLE] >>> ALICI (CENTRAL) CIHAZ BAGLANDI! <<<\n");
    }
}

static void disconnected(struct bt_conn *conn, uint8_t reason) {
    is_connected = false;
    notify_enabled = false;
    if (active_conn) {
        bt_conn_unref(active_conn);
        active_conn = NULL;
    }
    printf("\n[BLE] --- BAGLANTI KOPTU (Sebep: %u) ---\n", reason);
}

BT_CONN_CB_DEFINE(conn_callbacks) = {
    .connected = connected,
    .disconnected = disconnected,
};

#define MY_ADV_PARAM BT_LE_ADV_PARAM(BT_LE_ADV_OPT_CONN, \
                                     BT_GAP_ADV_FAST_INT_MIN_2, \
                                     BT_GAP_ADV_FAST_INT_MAX_2, \
                                     NULL)

void ble_server_init(void) {
    int err = bt_enable(NULL);
    if (err) {
        printf("[BLE HATA] Baslatilamadi (Kod: %d)\n", err);
        return;
    }
    bt_le_adv_start(MY_ADV_PARAM, ad, ARRAY_SIZE(ad), sd, ARRAY_SIZE(sd));
    printf("[BLE] Yayin basladi. Alici cihaz bekleniyor...\n");
}

bool ble_is_connected_and_ready(void) {
    return (is_connected && notify_enabled);
}

void ble_send_audio_data(int16_t *data, int total_samples) {
    int samples_sent = 0;
    int enomem_count = 0;

    /* MTU'ya gore dinamik paket boyutu hesapla */
    /* ATT Notify header = 3 byte, geri kalani PCM verisi */
    uint16_t mtu = 23; /* varsayilan */
    if (active_conn) {
        mtu = bt_gatt_get_mtu(active_conn);
    }
    int max_payload = mtu - 3;  /* ATT Notify header cikar */
    int chunk_size = max_payload / (int)sizeof(int16_t);
    if (chunk_size < 1) chunk_size = 1;

    printf("\n[BLE] MTU=%u -> Paket basi %d ornek (%d byte)\n", mtu, chunk_size, chunk_size * 2);
    printf("[BLE] %d adet PCM ornegi havadan firlatiliyor...\n", total_samples);

    while (samples_sent < total_samples && ble_is_connected_and_ready()) {
        int to_send = total_samples - samples_sent;
        if (to_send > chunk_size) {
            to_send = chunk_size;
        }

        const struct bt_gatt_attr *attr = bt_gatt_attr_next(&my_custom_svc.attrs[1]);

        int ret = bt_gatt_notify(active_conn, attr, &data[samples_sent], to_send * sizeof(int16_t));

        if (ret == 0) {
            samples_sent += to_send;
            enomem_count = 0;
            /* Buyuk MTU ile daha az paket -> daha kisa uyku yeterli */
            k_sleep(K_MSEC(2));
            
        } else if (ret == -ENOMEM || ret == -ENOBUFS || ret == -EAGAIN) {
            enomem_count++;
            if (enomem_count % 50 == 0) {
                printf("[UYARI] Hafiza sisti! %d. ornekte radyonun bosalmasi bekleniyor...\n", samples_sent);
            }
            k_sleep(K_MSEC(10));
            
        } else {
            printf("[BLE KRIZ] Gonderim REDDEDILDI! (Kod: %d)\n", ret);
            k_sleep(K_MSEC(50));
        }
    printf("\n[BLE] ISLEM TAMAMLANDI! %d ornek gonderildi.\n", samples_sent);
}
#else
void ble_server_init(void) {}
bool ble_is_connected_and_ready(void) { return true; }
void ble_send_audio_data(int16_t *data, int total_samples) {
    (void)data;
    (void)total_samples;
}
#endif
```

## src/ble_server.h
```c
#ifndef BLE_SERVER_H
#define BLE_SERVER_H

#include <stdbool.h>
#include <stdint.h>

#ifdef __cplusplus
extern "C" {
#endif

void ble_server_init(void);
bool ble_is_connected_and_ready(void);
void ble_send_audio_data(int16_t *data, int total_samples);

#ifdef __cplusplus
}
#endif

#endif /* BLE_SERVER_H */
```

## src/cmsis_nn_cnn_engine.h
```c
#ifndef CMSIS_NN_CNN_ENGINE_H
#define CMSIS_NN_CNN_ENGINE_H

#include <stdint.h>
#include <stdbool.h>

#ifdef __cplusplus
extern "C" {
#endif

// Initializes CMSIS-NN ping-pong buffers & context
void cmsis_nn_cnn_init(void);

// Runs the 5-layer 2D CNN with shared 98.5 KB ping-pong buffers directly on Cortex-M33
// Input: [52, 313] INT8 Spectrogram (scale=0.093125, zp=20)
// Output: [13, 40, 32] INT8 Feature Map (scale=0.155061, zp=5)
int cmsis_nn_cnn_run(const int8_t *input_spec_int8, int8_t *ping_pong_A, int8_t *ping_pong_B, int8_t *out_features_int8);

// Output Feature Map Quantization Parameters
#define CMSIS_CNN_OUTPUT_SCALE      0.035800964f
#define CMSIS_CNN_OUTPUT_ZERO_POINT -17

#ifdef __cplusplus
}
#endif

#endif // CMSIS_NN_CNN_ENGINE_H
```

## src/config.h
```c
#ifndef CONFIG_H
#define CONFIG_H

#include <stdint.h>

#ifdef __cplusplus
extern "C" {
#endif

/* ============================================================================
 * AUDIO HARDWARE CONFIGURATION
 * ============================================================================ */
#define SAMPLE_RATE             16000
#define RECORD_SECONDS          5
#define TOTAL_SAMPLES           (SAMPLE_RATE * RECORD_SECONDS) /* 80000 samples */
#define AUDIO_RING_BUFFER_SAMPLES (SAMPLE_RATE * 1)            /* 16000 samples (1.0s) = 32 KB RAM (Full Acoustic Fidelity) */
#define DUMP_RECORD_SECONDS     3                              /* 3 seconds quick dump = 48000 samples */
#define DUMP_TOTAL_SAMPLES      (SAMPLE_RATE * DUMP_RECORD_SECONDS)
#define AUDIO_SOFTWARE_GAIN_MULTIPLIER 48                      /* 48x Software Digital Gain (Full Acoustic Dynamic Range) */

/* ============================================================================
 * FIRMWARE OPERATING MODES
 * MODE_REALTIME_INFERENCE    : Continuous Real-Time Environmental Sound Classification
 * MODE_AUDIO_DUMP_TO_PC      : Stream 3-Sec Raw Microphone Audio to PC over UART (WAV)
 * MODE_INJECT_GOLDEN_SAMPLE  : Benchmark Golden Pre-Recorded Audio (No Mic)
 * ============================================================================ */
#define MODE_REALTIME_INFERENCE    0
#define MODE_AUDIO_DUMP_TO_PC      1
#define MODE_INJECT_GOLDEN_SAMPLE  2

#define FIRMWARE_OPERATION_MODE    MODE_REALTIME_INFERENCE /* Live Microphone Real-Time Sound Inference */
#define SILENCE_AC_RMS_THRESHOLD   3500                    /* Increased squelch threshold: Ignores fan/ambient noise (<3500) */

/* ============================================================================
 * 🎛️ TINYML MODEL PROFILE CONFIGURATION (Select your Hardware Tier)
 * PROFILE_FLAGSHIP_DENSE_91   : 🏆 90.50% Accuracy, 80.4% Live Keystrokes (866 KB Flash, 490 ms GRU / 764 ms Total)
 * PROFILE_SPARSE_PRUNED_48K   : ⚡ 88.50% Accuracy, CSR Zero-Skipping (620 KB Flash, 373 ms GRU / 647 ms Total)
 * PROFILE_INT8_FIXED_SIMD_91  : 🚀 91.50% Accuracy, Full 5.0s INT8 SIMD (586 KB Flash, 172 KB Arena, 229 ms GRU)
 * PROFILE_CMSIS_NN_PINGPONG_91: 👑 91.50% Accuracy, Native CMSIS-NN Ping-Pong (540 KB Flash, 98 KB Arena, 55% SRAM!)
 * PROFILE_TCN_85              : ⚡ 85.25% Accuracy, 1D Dilated TC-ResNet (~92.8 KB Flash, 10.2 KB SRAM)
 * PROFILE_SLIM_TCN_81         : 🪶 80.50% Accuracy, Slim Channel-Pruned TCN (~47.6 KB Flash, 7.5 KB SRAM) [<50 KB]
 * ============================================================================ */
#define PROFILE_FLAGSHIP_DENSE_91    1
#define PROFILE_SPARSE_PRUNED_48K    2
#define PROFILE_INT8_FIXED_SIMD_91   3
#define PROFILE_CMSIS_NN_PINGPONG_91 4
#define PROFILE_TCN_85               5
#define PROFILE_SLIM_TCN_81          6

#define ACTIVE_MODEL_PROFILE         PROFILE_SLIM_TCN_81

#define ENABLE_STREAMING_INFERENCE         true
#define ENABLE_BLE_COMMUNICATION           false /* Set to false for standalone microphone audio inference over UART */

/* Sliding window stride in seconds for continuous mode (e.g. 1 sec hop) */
#define INFERENCE_STREAMING_STRIDE_SEC     1
#define INFERENCE_STREAMING_STRIDE_SAMPLES (SAMPLE_RATE * INFERENCE_STREAMING_STRIDE_SEC)

/* ============================================================================
 * AUDIO PREPROCESSING & MEL-SPECTROGRAM CONFIGURATION
 * ============================================================================ */
#define FFT_SIZE                512
#define HOP_LENGTH              256
#define N_MELS                  52
#define NUM_FREQ_BINS           (FFT_SIZE / 2 + 1) /* 257 bins */

/* Model expects 313 time frames (5 seconds @ 16kHz with 256 hop, center=True). */
#define SPECTROGRAM_TIME_STEPS  313
#define SPECTROGRAM_TOTAL_ELEMENTS (N_MELS * SPECTROGRAM_TIME_STEPS) /* 52 * 313 = 16276 */

/* ============================================================================
 * TENSORFLOW LITE MICRO CONFIGURATION
 * ============================================================================ */
#if (ACTIVE_MODEL_PROFILE == PROFILE_CMSIS_NN_PINGPONG_91)
    #define TFLM_TENSOR_ARENA_SIZE  (4 * 1024) /* TFLM Arena eliminated! Native CMSIS-NN uses 98 KB ping-pong */
#else
    #define TFLM_TENSOR_ARENA_SIZE  (172 * 1024) /* 172 KB RAM Arena for TFLM */
#endif
#define TFLM_NUM_OPS            8
#define NUM_ESC50_CLASSES       50

/* ============================================================================
 * ESC-50 CLASS NAMES (Exact Alphabetical Match with Trained Model)
 * ============================================================================ */
static const char* const ESC50_CLASS_NAMES[NUM_ESC50_CLASSES] = {
    "airplane",            "breathing",           "brushing teeth",      "can opening",         "car horn",
    "cat",                 "chainsaw",            "chirping birds",      "church bells",        "clapping",
    "clock alarm",         "clock tick",          "coughing",            "cow",                 "crackling fire",
    "crickets",            "crow",                "crying baby",         "dog",                 "door wood creaks",
    "door wood knock",     "drinking sipping",    "engine",              "fireworks",           "footsteps",
    "frog",                "glass breaking",      "hand saw",            "helicopter",          "hen",
    "insects",             "keyboard typing",     "laughing",            "mouse click",         "pig",
    "pouring water",       "rain",                "rooster",             "sea waves",           "sheep",
    "siren",               "sneezing",            "snoring",             "thunderstorm",        "toilet flush",
    "train",               "vacuum cleaner",      "washing machine",     "water drops",         "wind"
};

#ifdef __cplusplus
}
#endif

#endif /* CONFIG_H */
```
